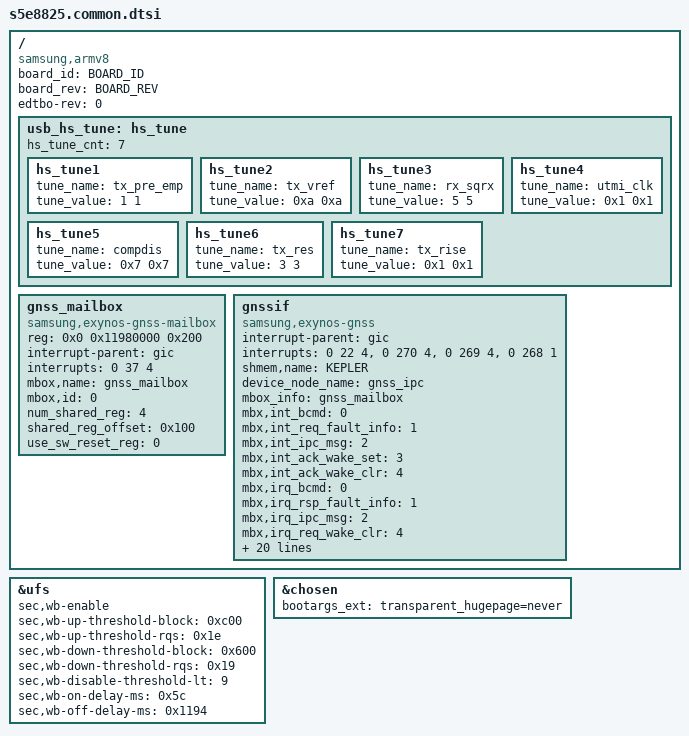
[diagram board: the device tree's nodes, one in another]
/*
 * SAMSUNG S5E8825 SoC device tree source
 *
 * Copyright (c) 2020 Samsung Electronics Co., Ltd.
 *             http://www.samsung.com
 *
 * SAMSUNG S5E8825 SoC device nodes are listed in this file.
 * EXYNOS based board files can include this file and provide
 * values for board specfic bindings.
 *
 * This program is free software; you can redistribute it and/or modify
 * it under the terms of the GNU General Public License version 2 as
 * published by the Free Software Foundation.
 */

#include <dt-bindings/interrupt-controller/s5e8825.h>
#include <dt-bindings/gpio/gpio.h>
#include <dt-bindings/clock/s5e8825.h>
#include "../erd/s5e8825-cp-s5308ap-sipc.dtsi"
#include "../erd/s5e8825-erd8825-dit.dtsi"
#include "sec_reboot.dtsi"

#define BOARD_ID        0x1
#define BOARD_REV       0x0

/ {
	compatible = "samsung,armv8", "samsung,s5e8825";
	board_id = <BOARD_ID>;
	board_rev = <BOARD_REV>;
	edtbo-rev = <0>;
};

/ {
	fragment@model {
		target-path = "/";

		__overlay__ {
			#address-cells = <2>;
			#size-cells = <1>;

			usb_hs_tune: hs_tune {
				hs_tune_cnt = <7>;

				/* value = <device host> */
				hs_tune1 {
					tune_name = "tx_pre_emp";
					tune_value = <1 1>;
				};

				hs_tune2 {
					tune_name = "tx_vref";
					tune_value = <0xa 0xa>;
				};

				hs_tune3 {
					tune_name = "rx_sqrx";
					tune_value = <5 5>;
				};

				hs_tune4 {
					tune_name = "utmi_clk";
					tune_value = <0x1 0x1>;
				};

				hs_tune5 {
					tune_name = "compdis";
					tune_value = <0x7 0x7>;
				};

				hs_tune6 {
					tune_name = "tx_res";
					tune_value = <3 3>;
				};

				hs_tune7 {
					tune_name = "tx_rise";
					tune_value = <0x1 0x1>;
				};
			};

			/*			usb_notifier {
							compatible = "samsung,usb-notifier";
							udc = <&udc>;
							status = "okay";
						};
			 */
			gnss_mailbox: gnss_mailbox {
				status = "okay";
				compatible = "samsung,exynos-gnss-mailbox";
				reg = <0x0 0x11980000 0x200>; /* MAILBOX AP2GNSS */
				interrupt-parent = <&gic>;
				interrupts = <0 37 4>;
				mbox,name = "gnss_mailbox";
				mbox,id = <0>;
				num_shared_reg = <4>;
				shared_reg_offset = <0x100>;
				use_sw_reset_reg = <0>;
			};

			gnssif {
				status = "okay";
				compatible = "samsung,exynos-gnss";
				interrupt-parent = <&gic>;
				interrupts = <0 22 4>,
				<0 270 4>,
				<0 269 4>,
				<0 268 1>;
				interrupt-names = "ACTIVE", "WATCHDOG", "WAKEUP", "SW_INIT";
				shmem,name = "KEPLER";
				device_node_name = "gnss_ipc";
				/* Mailbox */
				mbox_info = <&gnss_mailbox>;
				/* ap2gnss */
				mbx,int_bcmd = <0>;
				mbx,int_req_fault_info = <1>;
				mbx,int_ipc_msg = <2>;
				mbx,int_ack_wake_set = <3>;
				mbx,int_ack_wake_clr = <4>;
				/* gnss2ap */
				mbx,irq_bcmd = <0>;
				mbx,irq_rsp_fault_info = <1>;
				mbx,irq_ipc_msg = <2>;
				mbx,irq_req_wake_clr = <4>;
				mbx,irq_simple_lock = <15>;
				mbx,reg_bcmd_ctrl = <0>, <1>, <2>, <3>;
				/* Memory */
				memory-region = <&gnss_rmem>;
				reg_rx_ipc_msg = <1 5>;
				reg_tx_ipc_msg = <1 4>;
				reg_rx_head = <1 3>;
				reg_rx_tail = <1 2>;
				reg_tx_head = <1 1>;
				reg_tx_tail = <1 0>;
				fault_info = <1 0x200000 0x180000>;
				shmem,code_offset = <0x00000000>;
				shmem,code_allowed_size = <0x00380000>;
				shmem,ipc_offset = <0x00380000>;
				shmem,ipc_size = <0x00080000>;
				shmem,ipc_rx_offset = <0x00000000>;
				shmem,ipc_rx_size = <0x00040000>;
				shmem,ipc_tx_offset = <0x00040000>;
				shmem,ipc_tx_size = <0x0003FF80>;
				shmem,ipc_reg_offset = <0x0007FF80>;
				shmem,ipc_reg_size = <0x00000080>; /* can afford 32 regs */
			}; /* end of gnssif */
		}; /* end of __overlay__ */
	}; /* end of fragment */
};

&ufs {
	sec,wb-enable;
	sec,wb-up-threshold-block = <0xc00>;
	sec,wb-up-threshold-rqs = <0x1e>;
	sec,wb-down-threshold-block = <0x600>;
	sec,wb-down-threshold-rqs = <0x19>;
	sec,wb-disable-threshold-lt = <9>;
	sec,wb-on-delay-ms = <0x5c>;
	sec,wb-off-delay-ms = <0x1194>;
};

&chosen {
	bootargs_ext = "transparent_hugepage=never";
};
